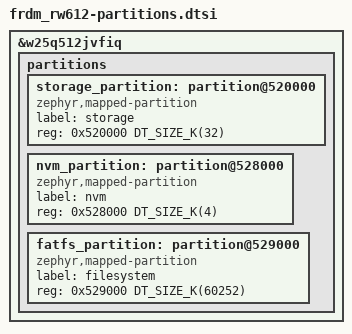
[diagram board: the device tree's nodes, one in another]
/* Partition layout for frdm_rw612: the flash memory map shared by the
 * bootloader and every application image. Generated by
 * tools/partition_layout.py; do not edit by hand -- re-run
 * `python3 tools/partition_layout.py --fix frdm_rw612` after changing
 * the upstream board geometry or tools/boards.toml.
 *
 * Board-specific overlay glue (delete-nodes, device enablement,
 * aliases/chosen) lives in dts/nxp/frdm_rw612.dtsi, which includes
 * this file.
 */

&w25q512jvfiq {
	partitions {

		/* Inherited from the upstream board dts and kept as-is
		 * (not re-emitted here):
		 *   mcuboot (boot_partition): 0x0 + DT_SIZE_K(128)
		 *   image-0 (slot0_partition): 0x20000 + DT_SIZE_M(2)
		 *   image-1 (slot1_partition): 0x320000 + DT_SIZE_M(2)
		 */

		storage_partition: partition@520000 {
			compatible = "zephyr,mapped-partition";
			label = "storage";
			reg = <0x520000 DT_SIZE_K(32)>;
		};

		nvm_partition: partition@528000 {
			compatible = "zephyr,mapped-partition";
			label = "nvm";
			reg = <0x528000 DT_SIZE_K(4)>;
		};

		fatfs_partition: partition@529000 {
			compatible = "zephyr,mapped-partition";
			label = "filesystem";
			reg = <0x529000 DT_SIZE_K(60252)>;
		};
	};
};
